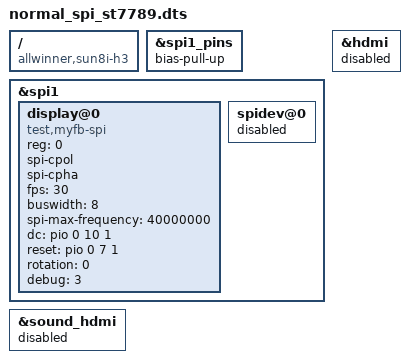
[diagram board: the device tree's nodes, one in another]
/dts-v1/;
/plugin/;

/ {
        compatible = "allwinner,sun8i-h3";
        fragment@0 {
                target = <&spi1_pins>;
                __overlay__ {
                        bias-pull-up;
                };
        };

        fragment@1 {
                target = <&spi1>;
                __overlay__ {
                        /* needed to avoid dtc warning */
                        #address-cells = <1>;
                        #size-cells = <0>;
                        status = "okay";
                        display@0{
                                compatible = "test,myfb-spi", "sitronix,st7789v";
                                reg = <0>;
                                spi-cpol;
                                spi-cpha;
                                fps = <30>;
                                buswidth = <8>;
                                spi-max-frequency = <40000000>;
                                dc = <&pio 0 10 1>;
                                reset = <&pio 0 7 1>;
                                rotation = <0>;
                                status = "okay";
                                debug = <3>;
                        };
                        spidev@0{
                                status = "disable";
                        };
                };
        };


        fragment@2 {
                target = <&hdmi>;
                __overlay__ {
                        status = "disable";
                };
                   
        };
        fragment@3 {
                target = <&sound_hdmi>;
                __overlay__ {
                        status = "disable";
                };
        };
};
